# GD32F1x0 register map
File version: 1.0
CPU: CM3 r2p1, little endian, no MPU, no FPU, 4 interrupt priority bits
Registers are 32-bit, read-write, reset 0x0 unless marked. A register's access mark holds for its fields unless they carry their own. Offsets are from the block's base; [hi:lo] are bit positions; {n}, {i} and the like mark numbered series.

## DBG — Debug support
Base 0xE0042000
0x00 ID ro — MCU Device ID Code Register
  [31:0] ID_CODE — DBG ID code register
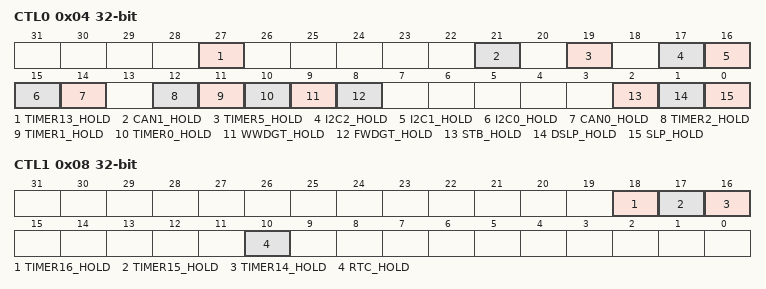
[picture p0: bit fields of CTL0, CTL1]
0x04 CTL0 — Debug Control Register 0
  [27] TIMER13_HOLD
  [21] CAN1_HOLD
  [19] TIMER5_HOLD
  [17] I2C2_HOLD
  [16] I2C1_HOLD
  [15] I2C0_HOLD
  [14] CAN0_HOLD
  [12] TIMER2_HOLD
  [11] TIMER1_HOLD
  [10] TIMER0_HOLD
  [9] WWDGT_HOLD
  [8] FWDGT_HOLD
  [2] STB_HOLD — Standby mode hold register
  [1] DSLP_HOLD — Deep-sleep mode hold register
  [0] SLP_HOLD — Sleep mode hold register
0x08 CTL1 — Debug Control Register 1
  [18] TIMER16_HOLD, [17] TIMER15_HOLD, [16] TIMER14_HOLD, [10] RTC_HOLD

## DMA — DMA controller
Base 0x40020000
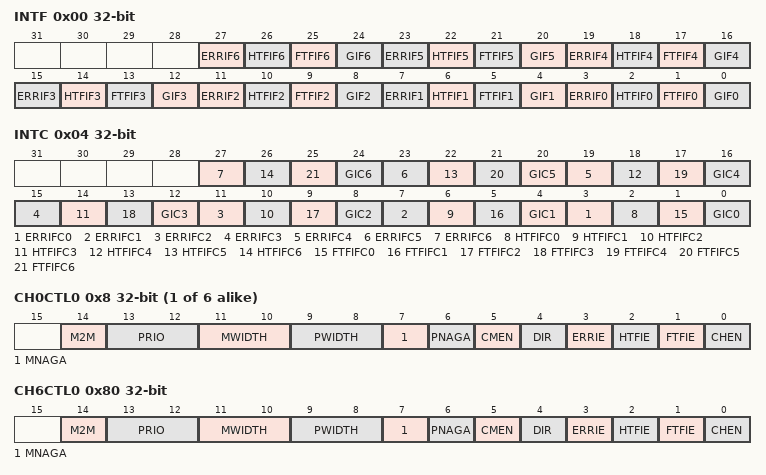
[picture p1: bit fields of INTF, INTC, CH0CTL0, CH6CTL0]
0x00 INTF ro — DMA interrupt flag register (DMA_INTF)
  [4n+3] ERRIF{n} (n=0..6) — Error flag of channel {n}
  [4n+2] HTFIF{n} (n=0..6) — Half transfer finish flag of channel {n}
  [4n+1] FTFIF{n} (n=0..6) — Full transfer finish flag of channel {n}
  [4n] GIF{n} (n=0..6) — Global interrupt flag of channel {n}
0x04 INTC wo — DMA interrupt flag clear register (DMA_INTC)
  [4n+3] ERRIFC{n} (n=0..6) — Clear bit for error flag of channel {n}
  [4n+2] HTFIFC{n} (n=0..6) — Clear bit for half transfer finish flag of channel {n}
  [4n+1] FTFIFC{n} (n=0..6) — Clear bit for Full transfer finish flag of channel {n}
  [4n] GIC{n} (n=0..6) — Clear global interrupt flag of channel {n}
{0x8+0x14*i} CH{i}CTL0 (i=0..5) — DMA channel configuration register (DMA_CH{i}CTL0)
  [14] M2M — Memory to memory mode
  [13:12] PRIO — Priority Level of this channel
  [11:10] MWIDTH — Transfer data size of memory
  [9:8] PWIDTH — Transfer data size of peripheral
  [7] MNAGA — Next address generation algorithm of memory
  [6] PNAGA — Next address generation algorithm of peripheral
  [5] CMEN — Circular mode enable
  [4] DIR — Transfer direction
  [3] ERRIE — Enable bit for channel error interrupt
  [2] HTFIE — Enable bit for half transfer finish interrupt
  [1] FTFIE — Enable bit for full transfer finish interrupt
  [0] CHEN — Channel enable
{0xC+0x14*i} CH{i}CNT (i=0..6) — DMA channel {i} counter register
  [15:0] CNT — Transfer counter
{0x10+0x14*i} CH{i}PADDR (i=0..6) — DMA channel {i} peripheral base address register
  [31:0] PADDR — Peripheral base address
{0x14+0x14*i} CH{i}MADDR (i=0..6) — DMA channel {i} memory base address register
  [31:0] MADDR — Memory base address
0x80 CH6CTL0 — DMA channel configuration register (DMA_CH6CTL0)
  [14] M2M — Memory to memory mode
  [13:12] PRIO — Priority Level of this channel
  [11:10] MWIDTH — Transfer data size of memory
  [9:8] PWIDTH — Transfer data size of peripheral
  [7] MNAGA — Next address generation algorithm of memory
  [6] PNAGA — Next address generation algorithm of peripheral
  [5] CMEN — Circular mode enable
  [4] DIR — Transfer direction
  [3] ERRIE — Enable bit for channel error interrupt
  [2] HTFIE — Enable bit for full transfer finish interrupt
  [1] FTFIE — Enable bit for full transfer finish interrupt
  [0] CHEN — Channel enable

## EXTI — External interrupt/event controller
Base 0x40010400
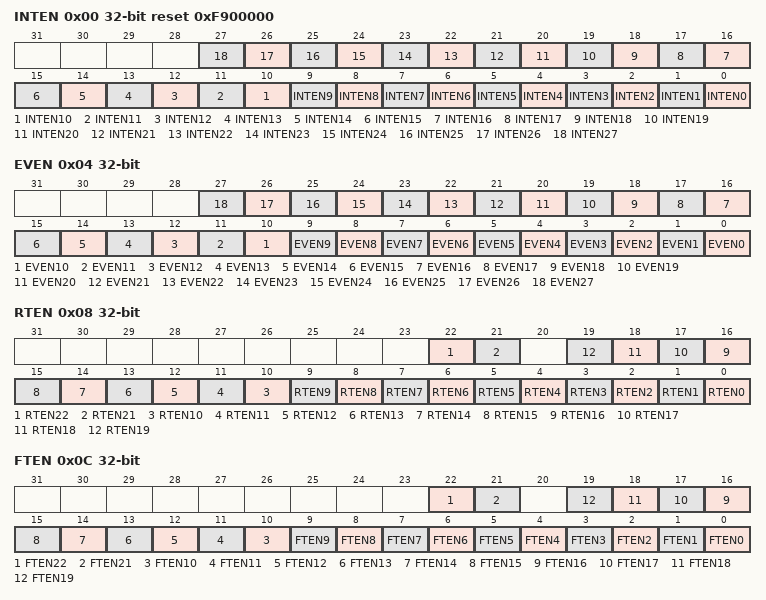
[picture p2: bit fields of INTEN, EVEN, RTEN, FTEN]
0x00 INTEN reset 0xF900000 — Interrupt enable register (EXTI_INTEN)
  [n] INTEN{n} (n=0..27) — Interrupt mask on line {n}
0x04 EVEN — Event enable register (EXTI_EVEN)
  [n] EVEN{n} (n=0..27) — Event enable on line {n}
0x08 RTEN — Rising Edge Trigger Enable register (EXTI_RTEN)
  [22] RTEN22 — Rising edge trigger enable of line 22
  [21] RTEN21 — Rising edge trigger enable of line 21
  [n] RTEN{n} (n=0..19) — Rising edge trigger enable of line {n}
0x0C FTEN — Falling Egde Trigger Enable register (EXTI_FTEN)
  [22] FTEN22 — Falling edge trigger enable of line 22
  [21] FTEN21 — Falling edge trigger enable of line 21
  [n] FTEN{n} (n=0..19) — Falling edge trigger enable of line {n}
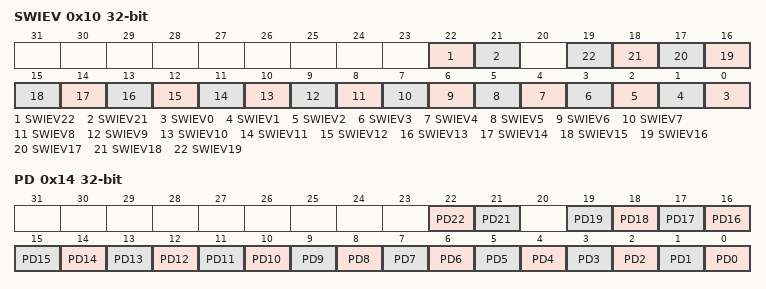
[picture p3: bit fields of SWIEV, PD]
0x10 SWIEV — Software interrupt event register (EXTI_SWIEV)
  [22] SWIEV22 — Interrupt/Event software trigger on line 22
  [21] SWIEV21 — Interrupt/Event software trigger on line 21
  [n] SWIEV{n} (n=0..19) — Interrupt/Event software trigger on line {n}
0x14 PD — Pending register (EXTI_PD)
  [22] PD22 — Interrupt pending status of line 22
  [21] PD21 — Interrupt pending status of line 21
  [n] PD{n} (n=0..19) — Interrupt pending status of line {n}
